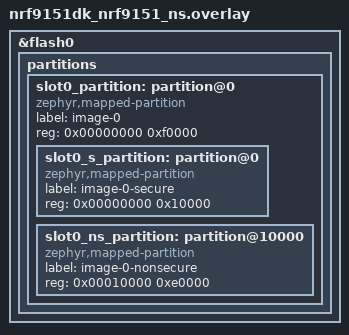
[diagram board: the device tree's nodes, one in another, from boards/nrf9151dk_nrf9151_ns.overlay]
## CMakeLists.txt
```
#
# Copyright (c) 2026 HARDWARIO a.s.
#
# SPDX-License-Identifier: LicenseRef-HARDWARIO-5-Clause
#

cmake_minimum_required(VERSION 3.20.0)

find_package(Zephyr REQUIRED HINTS $ENV{ZEPHYR_BASE})

project(application)

# Generates app_codec.h from codec/cbor-decoder.yaml
include(${ZEPHYR_HIO_ZEPHYR_SDK_MODULE_DIR}/cmake/app_codec.cmake)

target_sources(app PRIVATE src/main.c)
```

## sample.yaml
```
sample:
  name: HARDWARIO LTE + cloud uplink
tests:
  sample.hio.lte_cloud:
    build_only: true
    platform_allow: nrf9151dk/nrf9151/ns
    integration_platforms:
      - nrf9151dk/nrf9151/ns
    tags: hio hio_lte hio_cloud
```

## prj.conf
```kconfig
CONFIG_HIO_DEFAULTS=y
CONFIG_HIO_LOG=y
CONFIG_HIO_SHELL=y

# hio_info needs the VERSION file (app_version.h) next to CMakeLists.txt
CONFIG_HIO_INFO=y

CONFIG_HIO_CLOUD=y

# SHA-256 via PSA Crypto (provided by TF-M on _ns targets); the mbedTLS legacy
# backend does not configure on NCS v3.4 and TinyCrypt is not available.
CONFIG_HIO_CLOUD_HASH_PSA=y

# The minimal TF-M profile is enough for PSA SHA-256. The application uses
# almost the whole flash, see boards/nrf9151dk_nrf9151_ns.overlay.
CONFIG_TFM_PROFILE_TYPE_MINIMAL=y
```

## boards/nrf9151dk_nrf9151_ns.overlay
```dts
/*
 * Copyright (c) 2026 HARDWARIO a.s.
 *
 * SPDX-License-Identifier: LicenseRef-HARDWARIO-5-Clause
 */

/*
 * Flash layout without MCUboot (NCS v3.4 uses devicetree partitions, TF-M
 * reads them from slot0_s_partition / slot0_ns_partition):
 *
 * 0x0000_0000 TF-M secure image      (64 KB, TF-M minimal profile ~32 KB)
 * 0x0001_0000 Non-secure application (896 KB)
 * 0x000f_0000 TF-M PS / ITS / OTP    (32 KB, unchanged)
 * 0x000f_8000 Non-secure storage     (32 KB, unchanged)
 *
 * The secure/non-secure boundary must stay aligned to the 32 KB SPU region.
 * For DFU with MCUboot use the default board layout instead.
 */

/delete-node/ &boot_partition;
/delete-node/ &slot0_partition;
/delete-node/ &slot1_partition;

&flash0 {
	partitions {
		slot0_partition: partition@0 {
			compatible = "zephyr,mapped-partition";
			label = "image-0";
			reg = <0x00000000 0xf0000>;
			ranges = <0x0 0x0 0xf0000>;
			#address-cells = <1>;
			#size-cells = <1>;

			slot0_s_partition: partition@0 {
				compatible = "zephyr,mapped-partition";
				label = "image-0-secure";
				reg = <0x00000000 0x10000>;
			};

			slot0_ns_partition: partition@10000 {
				compatible = "zephyr,mapped-partition";
				label = "image-0-nonsecure";
				reg = <0x00010000 0xe0000>;
			};
		};
	};
};
```

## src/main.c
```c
/*
 * Copyright (c) 2026 HARDWARIO a.s.
 *
 * SPDX-License-Identifier: LicenseRef-HARDWARIO-5-Clause
 */

/* HIO includes */
#include <hio/hio_cloud.h>
#include <hio/hio_log.h>

/* Zephyr includes */
#include <zephyr/kernel.h>

/* Standard includes */
#include <stdint.h>

/* zcbor includes */
#include <zcbor_encode.h>

/* Generated from codec/cbor-decoder.yaml at build time */
#include <app_codec.h>

LOG_MODULE_REGISTER(main, LOG_LEVEL_DBG);

#define CLOUD_INIT_TIMEOUT K_MINUTES(10)
#define CLOUD_SEND_TIMEOUT K_MINUTES(2)

/* Message layout (keys from app_codec.h):
 *   { CODEC_KEY_E_SYSTEM: { CODEC_KEY_E_SYSTEM__UPTIME: <seconds> } } */
static int encode(zcbor_state_t *zs)
{
	zs->constant_state->stop_on_error = true;

	zcbor_map_start_encode(zs, ZCBOR_VALUE_IS_INDEFINITE_LENGTH);

	zcbor_uint32_put(zs, CODEC_KEY_E_SYSTEM);
	{
		zcbor_map_start_encode(zs, ZCBOR_VALUE_IS_INDEFINITE_LENGTH);

		zcbor_uint32_put(zs, CODEC_KEY_E_SYSTEM__UPTIME);
		zcbor_uint32_put(zs, (uint32_t)(k_uptime_get() / MSEC_PER_SEC));

		zcbor_map_end_encode(zs, ZCBOR_VALUE_IS_INDEFINITE_LENGTH);
	}

	zcbor_map_end_encode(zs, ZCBOR_VALUE_IS_INDEFINITE_LENGTH);

	if (!zcbor_check_error(zs)) {
		LOG_ERR("Encoding failed: %d", zcbor_peek_error(zs));
		return -EFAULT;
	}

	return 0;
}

int main(void)
{
	int ret;

	/* Decoder (codec/cbor-decoder.yaml) and its hash; hio_cloud uploads the
	 * decoder to the cloud when the hash differs from the session. */
	CODEC_CLOUD_OPTIONS_STATIC(cloud_options);

	LOG_INF("Starting application");

	/* hio_cloud brings up LTE (hio_lte_enable) itself. The claim token and
	 * serial number come from hio_info (PIB or "info" config). */
	ret = hio_cloud_init(&cloud_options);
	if (ret) {
		LOG_ERR("Call `hio_cloud_init` failed: %d", ret);
		return ret;
	}

	ret = hio_cloud_wait_initialized(CLOUD_INIT_TIMEOUT);
	if (ret) {
		LOG_ERR("Call `hio_cloud_wait_initialized` failed: %d", ret);
		return ret;
	}

	static uint8_t buf[64];

	ZCBOR_STATE_E(zs, 2, buf, sizeof(buf), 1);

	ret = encode(zs);
	if (ret) {
		LOG_ERR("Call `encode` failed: %d", ret);
		return ret;
	}

	size_t len = zs[0].payload_mut - buf;

	ret = hio_cloud_send_data(buf, len, CLOUD_SEND_TIMEOUT);
	if (ret) {
		LOG_ERR("Call `hio_cloud_send_data` failed: %d", ret);
		return ret;
	}

	LOG_INF("Message sent (%u bytes)", len);

	return 0;
}
```
